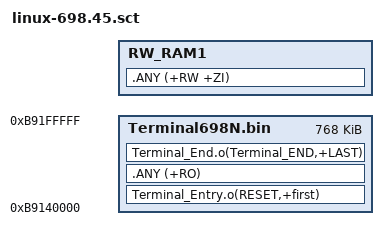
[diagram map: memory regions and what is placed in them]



LOAD_Terminal 0xB9140000 0x000C0000;//768K
{
  Terminal698N.bin 0xB9140000 0x000C0000;//768K
  {
;//Entry
		Terminal_Entry.o(RESET,+first)
;		*(InRoot$$Sections);//__main()的一部分
    .ANY (+RO)
		
;//End
		Terminal_End.o(Terminal_END,+LAST)
  }
	
	RW_RAM1 +0;RW_RAM1 start address is after ER_ROM1
	{
		.ANY (+RW +ZI)
	}
	;ARM_LIB_HEAP  0x00100000 EMPTY  0x00080000   {}
	;ARM_LIB_STACK 0x00180000 EMPTY -0x00080000   {}
}



